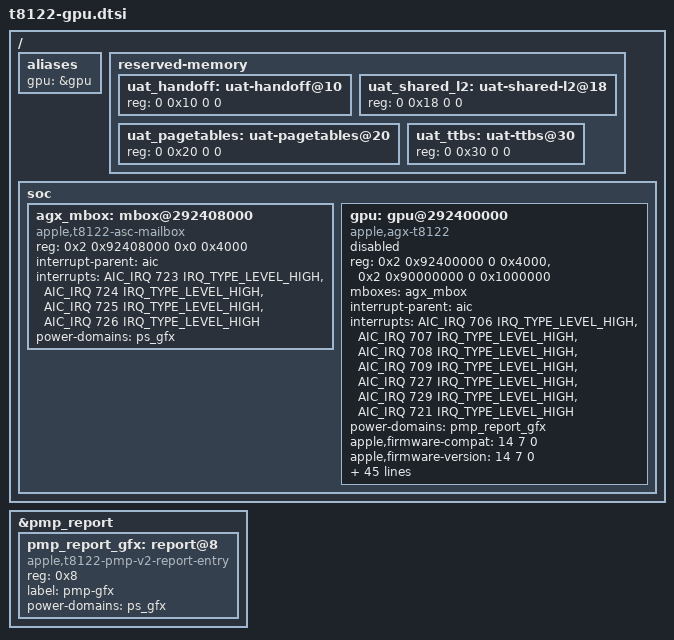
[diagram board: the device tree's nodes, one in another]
// SPDX-License-Identifier: GPL-2.0-only
/*
 * The M3's GPU (G15G), not run: no such Mac. Addresses, interrupts and
 * gpu-* values are t8122's ADT's (j504, the 14.8.3 template; j613 and j615
 * have the same, the iMacs' differences are in their board files). m1n1
 * fills the UAT regions, the perf-state table and the SRAM floor from the
 * live ADT; the driver reads the GPU's ID and perf-state maps from the GPU
 * (spec/agx-g15c/g15g.md).
 */

/ {
	aliases {
		gpu = &gpu;
	};

	reserved-memory {
		/* m1n1 sets them from the ADT's gfx-handoff, gfx-shared-l2-region,
		 * gfx-shared-region and gpu-region; empty until then
		 */
		uat_handoff: uat-handoff@10 {
			reg = <0 0x10 0 0>;
		};

		uat_shared_l2: uat-shared-l2@18 {
			reg = <0 0x18 0 0>;
		};

		uat_pagetables: uat-pagetables@20 {
			reg = <0 0x20 0 0>;
		};

		uat_ttbs: uat-ttbs@30 {
			reg = <0 0x30 0 0>;
		};
	};

	soc {
		/* The ADT's gfx-asc (0x82400000) and sgx (0x80000000) regs are
		 * bus addresses; arm-io maps bus 0 to CPU 0x2_1000_0000. The
		 * driver runs RTKit through the gfx-asc mailbox (ASC +0x8000).
		 */
		agx_mbox: mbox@292408000 {
			compatible = "apple,t8122-asc-mailbox", "apple,asc-mailbox-v4";
			reg = <0x2 0x92408000 0x0 0x4000>;
			interrupt-parent = <&aic>;
			/* the ADT's gfx-asc interrupts 0x2d4 0x2d3 0x2d6 0x2d5 */
			interrupts = <AIC_IRQ 723 IRQ_TYPE_LEVEL_HIGH>,
				     <AIC_IRQ 724 IRQ_TYPE_LEVEL_HIGH>,
				     <AIC_IRQ 725 IRQ_TYPE_LEVEL_HIGH>,
				     <AIC_IRQ 726 IRQ_TYPE_LEVEL_HIGH>;
			interrupt-names = "send-empty", "send-not-empty",
					  "recv-empty", "recv-not-empty";
			power-domains = <&ps_gfx>;
			#mbox-cells = <0>;
		};

		gpu: gpu@292400000 {
			compatible = "apple,agx-t8122", "gpu,t8122";
			reg = <0x2 0x92400000 0 0x4000>,
			      <0x2 0x90000000 0 0x1000000>;
			reg-names = "asc", "sgx";
			mboxes = <&agx_mbox>;
			/* the GPU's own interrupts, in the ADT's order (index 5
			 * invalid, interrupts-valid = 0x5f)
			 */
			interrupt-parent = <&aic>;
			interrupts = <AIC_IRQ 706 IRQ_TYPE_LEVEL_HIGH>,
				     <AIC_IRQ 707 IRQ_TYPE_LEVEL_HIGH>,
				     <AIC_IRQ 708 IRQ_TYPE_LEVEL_HIGH>,
				     <AIC_IRQ 709 IRQ_TYPE_LEVEL_HIGH>,
				     <AIC_IRQ 727 IRQ_TYPE_LEVEL_HIGH>,
				     <AIC_IRQ 729 IRQ_TYPE_LEVEL_HIGH>,
				     <AIC_IRQ 721 IRQ_TYPE_LEVEL_HIGH>;

			/* GFX through the PMP, AGX's entry 8: G15's firmware
			 * stalls without the PMP online, so the GPU waits for
			 * the PMP's DT (APPLE_USE_PMP)
			 */
			power-domains = <&pmp_report_gfx>;
#ifndef APPLE_USE_PMP
			status = "disabled";
#endif

			apple,firmware-compat = <14 7 0>;
			apple,firmware-version = <14 7 0>;

			memory-region = <&uat_ttbs>, <&uat_pagetables>, <&uat_handoff>,
					<&uat_shared_l2>;
			memory-region-names = "ttbs", "pagetables", "handoff", "shared-l2";

			/* f32 cells are the bit patterns. The leakage, one per
			 * cluster (1): m1n1 sets both from t8122's fuses, as the
			 * kext. The SRAM floor is j514map's until m1n1 sets it (an
			 * estimate).
			 */
			apple,perf-base-pstate = <1>;
			apple,min-sram-microvolt = <815000>;
			apple,core-leak-coef = <0>;
			apple,sram-leak-coef = <0>;

			apple,perf-boost-ce-step = <0x32>;
			apple,perf-boost-min-util = <0x5a>;
			apple,perf-filter-drop-threshold = <0x0>;
			apple,perf-filter-time-constant = <0x5>;
			apple,perf-filter-time-constant2 = <0xc8>;
			apple,perf-integral-gain = <0x3f4c28f6>;	/* 0.7975f */
			apple,perf-integral-gain2 = <0x3f4c28f6>;	/* 0.7975f */
			apple,perf-integral-min-clamp = <0x0>;
			apple,perf-proportional-gain = <0x40accccd>;	/* 5.4f */
			apple,perf-proportional-gain2 = <0x40accccd>;	/* 5.4f */
			apple,perf-tgt-utilization = <0x55>;

			apple,ppm-filter-time-constant-ms = <0x64>;
			apple,ppm-ki = <0x42c23333>;	/* 97.1f */
			apple,ppm-kp = <0x4039999a>;	/* 2.9f */

			apple,pwr-filter-time-constant = <0x139>;
			apple,pwr-integral-gain = <0x3ca59586>;	/* 0.0202129f */
			apple,pwr-integral-min-clamp = <0x0>;
			apple,pwr-min-duty-cycle = <0x1e>;
			apple,pwr-proportional-gain = <0x40a90fdb>;	/* 5.283185f */

			apple,se-engagement-criteria = <0x258>;
			apple,se-filter-time-constant = <0x9>;
			apple,se-filter-time-constant-1 = <0x3>;
			apple,se-inactive-threshold = <0x9c4>;
			apple,se-ki = <0xc2480000>;	/* -50f */
			apple,se-ki-1 = <0xc2c80000>;	/* -100f */
			apple,se-kp = <0xc0a00000>;	/* -5f */
			apple,se-kp-1 = <0xc1200000>;	/* -10f */
			apple,se-reset-criteria = <0x32>;

			apple,avg-power-filter-tc-ms = <0x28>;
			apple,avg-power-ki-only = <0x428c0000>;	/* 70f */
			apple,avg-power-kp = <0x3ff9999a>;	/* 1.95f */
			apple,avg-power-min-duty-cycle = <0x1e>;
			apple,avg-power-target-filter-tc = <0x1>;

			apple,fast-die0-integral-gain = <0x43e10000>;	/* 450f */
			apple,fast-die0-proportional-gain = <0x42080000>;	/* 34f */

			apple,power-sample-period = <0x8>;
			apple,pwr-sample-period-aic-clks = <0x30d40>;	/* 200000 */
		};
	};
};

&pmp_report {
	/* AGX, entry 8 of the ADT's PMP soc-device table: requested only with
	 * GFX's PMGR state on (its parent), as on t6034
	 */
	pmp_report_gfx: report@8 {
		compatible = "apple,t8122-pmp-v2-report-entry",
			     "apple,t6000-pmp-v2-report-entry";
		reg = <0x8>;
		label = "pmp-gfx";
		#power-domain-cells = <0>;
		power-domains = <&ps_gfx>;
	};
};
